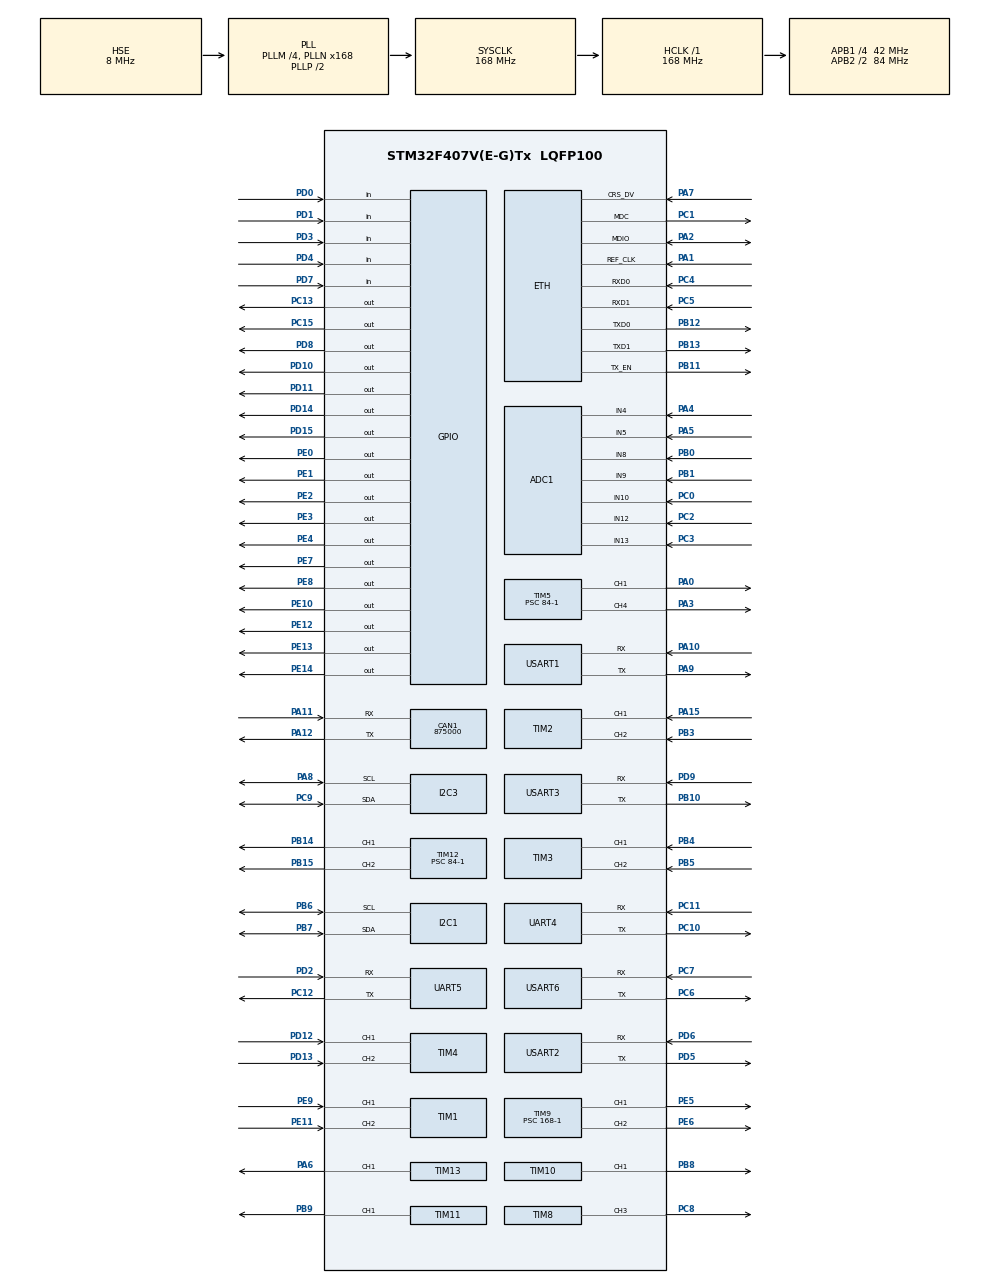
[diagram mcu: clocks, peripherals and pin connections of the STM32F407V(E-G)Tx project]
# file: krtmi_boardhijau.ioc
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ADC1.Channel-0\#ChannelRegularConversion=ADC_CHANNEL_4
ADC1.NbrOfConversionFlag=1
ADC1.Rank-0\#ChannelRegularConversion=1
ADC1.SamplingTime-0\#ChannelRegularConversion=ADC_SAMPLETIME_3CYCLES
ADC1.master=1
CAN1.CalculateBaudRate=875000
CAN1.CalculateTimeBit=1142
CAN1.CalculateTimeQuantum=380.95238095238096
Dma.Request0=UART4_RX
Dma.Request1=UART4_TX
Dma.Request2=UART5_RX
Dma.Request3=UART5_TX
Dma.Request4=USART2_RX
Dma.Request5=USART2_TX
Dma.Request6=USART3_RX
Dma.Request7=USART3_TX
Dma.Request8=USART6_RX
Dma.Request9=USART6_TX
Dma.UART4_RX.0.Direction=DMA_PERIPH_TO_MEMORY
Dma.UART4_RX.0.FIFOMode=DMA_FIFOMODE_DISABLE
Dma.UART4_RX.0.Instance=DMA1_Stream2
Dma.UART4_RX.0.MemDataAlignment=DMA_MDATAALIGN_BYTE
Dma.UART4_RX.0.MemInc=DMA_MINC_ENABLE
Dma.UART4_RX.0.Mode=DMA_NORMAL
Dma.UART4_RX.0.PeriphDataAlignment=DMA_PDATAALIGN_BYTE
Dma.UART4_RX.0.PeriphInc=DMA_PINC_DISABLE
Dma.UART4_RX.0.Priority=DMA_PRIORITY_LOW
Dma.UART4_TX.1.Direction=DMA_MEMORY_TO_PERIPH
Dma.UART4_TX.1.FIFOMode=DMA_FIFOMODE_DISABLE
Dma.UART4_TX.1.Instance=DMA1_Stream4
Dma.UART4_TX.1.MemDataAlignment=DMA_MDATAALIGN_BYTE
Dma.UART4_TX.1.MemInc=DMA_MINC_ENABLE
Dma.UART4_TX.1.Mode=DMA_NORMAL
Dma.UART4_TX.1.PeriphDataAlignment=DMA_PDATAALIGN_BYTE
Dma.UART4_TX.1.PeriphInc=DMA_PINC_DISABLE
Dma.UART4_TX.1.Priority=DMA_PRIORITY_LOW
Dma.UART5_RX.2.Direction=DMA_PERIPH_TO_MEMORY
Dma.UART5_RX.2.FIFOMode=DMA_FIFOMODE_DISABLE
Dma.UART5_RX.2.Instance=DMA1_Stream0
Dma.UART5_RX.2.MemDataAlignment=DMA_MDATAALIGN_BYTE
Dma.UART5_RX.2.MemInc=DMA_MINC_ENABLE
Dma.UART5_RX.2.Mode=DMA_NORMAL
Dma.UART5_RX.2.PeriphDataAlignment=DMA_PDATAALIGN_BYTE
Dma.UART5_RX.2.PeriphInc=DMA_PINC_DISABLE
Dma.UART5_RX.2.Priority=DMA_PRIORITY_HIGH
Dma.UART5_TX.3.Direction=DMA_MEMORY_TO_PERIPH
Dma.UART5_TX.3.FIFOMode=DMA_FIFOMODE_DISABLE
Dma.UART5_TX.3.Instance=DMA1_Stream7
Dma.UART5_TX.3.MemDataAlignment=DMA_MDATAALIGN_BYTE
Dma.UART5_TX.3.MemInc=DMA_MINC_ENABLE
Dma.UART5_TX.3.Mode=DMA_NORMAL
Dma.UART5_TX.3.PeriphDataAlignment=DMA_PDATAALIGN_BYTE
Dma.UART5_TX.3.PeriphInc=DMA_PINC_DISABLE
Dma.UART5_TX.3.Priority=DMA_PRIORITY_HIGH
Dma.USART2_RX.4.Direction=DMA_PERIPH_TO_MEMORY
Dma.USART2_RX.4.FIFOMode=DMA_FIFOMODE_DISABLE
Dma.USART2_RX.4.Instance=DMA1_Stream5
Dma.USART2_RX.4.MemDataAlignment=DMA_MDATAALIGN_BYTE
Dma.USART2_RX.4.MemInc=DMA_MINC_ENABLE
Dma.USART2_RX.4.Mode=DMA_NORMAL
Dma.USART2_RX.4.PeriphDataAlignment=DMA_PDATAALIGN_BYTE
Dma.USART2_RX.4.PeriphInc=DMA_PINC_DISABLE
Dma.USART2_RX.4.Priority=DMA_PRIORITY_LOW
Dma.USART2_TX.5.Direction=DMA_MEMORY_TO_PERIPH
Dma.USART2_TX.5.FIFOMode=DMA_FIFOMODE_DISABLE
Dma.USART2_TX.5.Instance=DMA1_Stream6
Dma.USART2_TX.5.MemDataAlignment=DMA_MDATAALIGN_BYTE
Dma.USART2_TX.5.MemInc=DMA_MINC_ENABLE
Dma.USART2_TX.5.Mode=DMA_NORMAL
Dma.USART2_TX.5.PeriphDataAlignment=DMA_PDATAALIGN_BYTE
Dma.USART2_TX.5.PeriphInc=DMA_PINC_DISABLE
Dma.USART2_TX.5.Priority=DMA_PRIORITY_LOW
Dma.USART3_RX.6.Direction=DMA_PERIPH_TO_MEMORY
Dma.USART3_RX.6.FIFOMode=DMA_FIFOMODE_DISABLE
Dma.USART3_RX.6.Instance=DMA1_Stream1
Dma.USART3_RX.6.MemDataAlignment=DMA_MDATAALIGN_BYTE
Dma.USART3_RX.6.MemInc=DMA_MINC_ENABLE
Dma.USART3_RX.6.Mode=DMA_NORMAL
Dma.USART3_RX.6.PeriphDataAlignment=DMA_PDATAALIGN_BYTE
Dma.USART3_RX.6.PeriphInc=DMA_PINC_DISABLE
Dma.USART3_RX.6.Priority=DMA_PRIORITY_LOW
Dma.USART3_TX.7.Direction=DMA_MEMORY_TO_PERIPH
Dma.USART3_TX.7.FIFOMode=DMA_FIFOMODE_DISABLE
Dma.USART3_TX.7.Instance=DMA1_Stream3
Dma.USART3_TX.7.MemDataAlignment=DMA_MDATAALIGN_BYTE
Dma.USART3_TX.7.MemInc=DMA_MINC_ENABLE
Dma.USART3_TX.7.Mode=DMA_NORMAL
Dma.USART3_TX.7.PeriphDataAlignment=DMA_PDATAALIGN_BYTE
Dma.USART3_TX.7.PeriphInc=DMA_PINC_DISABLE
Dma.USART3_TX.7.Priority=DMA_PRIORITY_LOW
Dma.USART6_RX.8.Direction=DMA_PERIPH_TO_MEMORY
Dma.USART6_RX.8.FIFOMode=DMA_FIFOMODE_DISABLE
Dma.USART6_RX.8.Instance=DMA2_Stream1
Dma.USART6_RX.8.MemDataAlignment=DMA_MDATAALIGN_BYTE
Dma.USART6_RX.8.MemInc=DMA_MINC_ENABLE
Dma.USART6_RX.8.Mode=DMA_NORMAL
Dma.USART6_RX.8.PeriphDataAlignment=DMA_PDATAALIGN_BYTE
Dma.USART6_RX.8.PeriphInc=DMA_PINC_DISABLE
Dma.USART6_RX.8.Priority=DMA_PRIORITY_LOW
Dma.USART6_TX.9.Direction=DMA_MEMORY_TO_PERIPH
Dma.USART6_TX.9.FIFOMode=DMA_FIFOMODE_DISABLE
Dma.USART6_TX.9.Instance=DMA2_Stream6
Dma.USART6_TX.9.MemDataAlignment=DMA_MDATAALIGN_BYTE
Dma.USART6_TX.9.MemInc=DMA_MINC_ENABLE
Dma.USART6_TX.9.Mode=DMA_NORMAL
Dma.USART6_TX.9.PeriphDataAlignment=DMA_PDATAALIGN_BYTE
Dma.USART6_TX.9.PeriphInc=DMA_PINC_DISABLE
Dma.USART6_TX.9.Priority=DMA_PRIORITY_LOW
ETH.MACAddr=12\:34\:56\:12\:34\:56
ETH.MediaInterface=HAL_ETH_RMII_MODE
LWIP.BSP.number=1
LWIP.GATEWAY_ADDRESS=192.168.013.100
LWIP.IP_ADDRESS=192.168.013.111
LWIP.LWIP_DHCP=0
LWIP.MEM_SIZE=10*1024
LWIP.NETMASK_ADDRESS=255.255.255.000
LWIP.Version=v2.1.2_Cube
LWIP0.BSP.STBoard=false
LWIP0.BSP.api=BSP_COMPONENT_DRIVER
LWIP0.BSP.component=LAN8742
LWIP0.BSP.instance=LAN8742
LWIP0.BSP.name=Driver_PHY
LWIP0.BSP.semaphore=S_LAN8742
LWIP0.BSP.solution=LAN8742
Mcu.Family=STM32F4
Mcu.Name=STM32F407V(E-G)Tx
Mcu.Package=LQFP100
NVIC.DMA1_Stream0_IRQn=true\:0\:0\:false\:false\:true\:false\:true\:true
NVIC.DMA1_Stream1_IRQn=true\:0\:0\:false\:false\:true\:false\:true\:true
NVIC.DMA1_Stream2_IRQn=true\:0\:0\:false\:false\:true\:false\:true\:true
NVIC.DMA1_Stream3_IRQn=true\:0\:0\:false\:false\:true\:false\:true\:true
NVIC.DMA1_Stream4_IRQn=true\:0\:0\:false\:false\:true\:false\:true\:true
NVIC.DMA1_Stream5_IRQn=true\:0\:0\:false\:false\:true\:false\:true\:true
NVIC.DMA1_Stream6_IRQn=true\:0\:0\:false\:false\:true\:false\:true\:true
NVIC.DMA1_Stream7_IRQn=true\:0\:0\:false\:false\:true\:false\:true\:true
NVIC.DMA2_Stream1_IRQn=true\:0\:0\:false\:false\:true\:false\:true\:true
NVIC.DMA2_Stream6_IRQn=true\:0\:0\:false\:false\:true\:false\:true\:true
NVIC.PriorityGroup=NVIC_PRIORITYGROUP_4
NVIC.TIM6_DAC_IRQn=true\:0\:0\:false\:false\:true\:true\:true\:true
NVIC.UART4_IRQn=true\:0\:0\:false\:false\:true\:true\:true\:true
NVIC.UART5_IRQn=true\:0\:0\:false\:false\:true\:true\:true\:true
NVIC.USART2_IRQn=true\:0\:0\:false\:false\:true\:true\:true\:true
NVIC.USART3_IRQn=true\:0\:0\:false\:false\:true\:true\:true\:true
PA0-WKUP.Signal=S_TIM5_CH1
PA1.Mode=RMII
PA1.Signal=ETH_REF_CLK
PA10.Mode=Asynchronous
PA10.Signal=USART1_RX
PA11.Mode=CAN_Activate
PA11.Signal=CAN1_RX
PA12.Mode=CAN_Activate
PA12.Signal=CAN1_TX
PA13.Mode=Serial_Wire
PA13.Signal=SYS_JTMS-SWDIO
PA14.Mode=Serial_Wire
PA14.Signal=SYS_JTCK-SWCLK
PA15.Signal=S_TIM2_CH1_ETR
PA2.Mode=RMII
PA2.Signal=ETH_MDIO
PA3.Signal=S_TIM5_CH4
PA4.Signal=ADCx_IN4
PA5.Signal=ADCx_IN5
PA6.Signal=S_TIM13_CH1
PA7.Mode=RMII
PA7.Signal=ETH_CRS_DV
PA8.Mode=I2C
PA8.Signal=I2C3_SCL
PA9.Mode=Asynchronous
PA9.Signal=USART1_TX
PB0.Signal=ADCx_IN8
PB1.Signal=ADCx_IN9
PB10.Mode=Asynchronous
PB10.Signal=USART3_TX
PB11.Mode=RMII
PB11.Signal=ETH_TX_EN
PB12.Mode=RMII
PB12.Signal=ETH_TXD0
PB13.Mode=RMII
PB13.Signal=ETH_TXD1
PB14.Signal=S_TIM12_CH1
PB15.Signal=S_TIM12_CH2
PB3.Signal=S_TIM2_CH2
PB4.Signal=S_TIM3_CH1
PB5.Signal=S_TIM3_CH2
PB6.Mode=I2C
PB6.Signal=I2C1_SCL
PB7.Mode=I2C
PB7.Signal=I2C1_SDA
PB8.Signal=S_TIM10_CH1
PB9.Signal=S_TIM11_CH1
PC0.Signal=ADCx_IN10
PC1.Mode=RMII
PC1.Signal=ETH_MDC
PC10.Mode=Asynchronous
PC10.Signal=UART4_TX
PC11.Mode=Asynchronous
PC11.Signal=UART4_RX
PC12.Mode=Asynchronous
PC12.Signal=UART5_TX
PC13-ANTI_TAMP.Signal=GPIO_Output
PC15-OSC32_OUT.Signal=GPIO_Output
PC2.Signal=ADCx_IN12
PC3.Signal=ADCx_IN13
PC4.Mode=RMII
PC4.Signal=ETH_RXD0
PC5.Mode=RMII
PC5.Signal=ETH_RXD1
PC6.Mode=Asynchronous
PC6.Signal=USART6_TX
PC7.Mode=Asynchronous
PC7.Signal=USART6_RX
PC8.Signal=S_TIM8_CH3
PC9.Mode=I2C
PC9.Signal=I2C3_SDA
PD0.GPIO_PuPd=GPIO_PULLUP
PD0.Signal=GPIO_Input
PD1.GPIO_PuPd=GPIO_PULLUP
PD1.Signal=GPIO_Input
PD10.Signal=GPIO_Output
PD11.Signal=GPIO_Output
PD12.Signal=S_TIM4_CH1
PD13.Signal=S_TIM4_CH2
PD14.Signal=GPIO_Output
PD15.Signal=GPIO_Output
PD2.Mode=Asynchronous
PD2.Signal=UART5_RX
PD3.GPIO_PuPd=GPIO_PULLUP
PD3.Signal=GPIO_Input
PD4.GPIO_PuPd=GPIO_PULLUP
PD4.Signal=GPIO_Input
PD5.Mode=Asynchronous
PD5.Signal=USART2_TX
PD6.Mode=Asynchronous
PD6.Signal=USART2_RX
PD7.GPIO_PuPd=GPIO_PULLUP
PD7.Signal=GPIO_Input
PD8.Signal=GPIO_Output
PD9.Mode=Asynchronous
PD9.Signal=USART3_RX
PE0.Signal=GPIO_Output
PE1.Signal=GPIO_Output
PE10.Signal=GPIO_Output
PE11.Signal=S_TIM1_CH2
PE12.Signal=GPIO_Output
PE13.Signal=GPIO_Output
PE14.Signal=GPIO_Output
PE2.Signal=GPIO_Output
PE3.Signal=GPIO_Output
PE4.Signal=GPIO_Output
PE5.Signal=S_TIM9_CH1
PE6.Signal=S_TIM9_CH2
PE7.Signal=GPIO_Output
PE8.Signal=GPIO_Output
PE9.Signal=S_TIM1_CH1
PH0-OSC_IN.Mode=HSE-External-Oscillator
PH0-OSC_IN.Signal=RCC_OSC_IN
PH1-OSC_OUT.Mode=HSE-External-Oscillator
PH1-OSC_OUT.Signal=RCC_OSC_OUT
ProjectManager.HeapSize=0x200
ProjectManager.StackSize=0x400
ProjectManager.TargetToolchain=STM32CubeIDE
RCC.48MHZClocksFreq_Value=84000000
RCC.AHBFreq_Value=168000000
RCC.APB1CLKDivider=RCC_HCLK_DIV4
RCC.APB1Freq_Value=42000000
RCC.APB1TimFreq_Value=84000000
RCC.APB2CLKDivider=RCC_HCLK_DIV2
RCC.APB2Freq_Value=84000000
RCC.APB2TimFreq_Value=168000000
RCC.CortexFreq_Value=168000000
RCC.HCLKFreq_Value=168000000
RCC.HSE_VALUE=8000000
RCC.HSI_VALUE=16000000
RCC.LSE_VALUE=32768
RCC.PLLM=4
RCC.PLLN=168
RCC.PLLSourceVirtual=RCC_PLLSOURCE_HSE
RCC.SYSCLKFreq_VALUE=168000000
RCC.SYSCLKSource=RCC_SYSCLKSOURCE_PLLCLK
RCC.VCOOutputFreq_Value=336000000
SH.ADCx_IN10.0=ADC1_IN10,IN10
SH.ADCx_IN12.0=ADC1_IN12,IN12
SH.ADCx_IN13.0=ADC1_IN13,IN13
SH.ADCx_IN4.0=ADC1_IN4,IN4
SH.ADCx_IN5.0=ADC1_IN5,IN5
SH.ADCx_IN8.0=ADC1_IN8,IN8
SH.ADCx_IN9.0=ADC1_IN9,IN9
SH.S_TIM10_CH1.0=TIM10_CH1,PWM Generation1 CH1
SH.S_TIM11_CH1.0=TIM11_CH1,PWM Generation1 CH1
SH.S_TIM12_CH1.0=TIM12_CH1,PWM Generation1 CH1
SH.S_TIM12_CH2.0=TIM12_CH2,PWM Generation2 CH2
SH.S_TIM13_CH1.0=TIM13_CH1,PWM Generation1 CH1
SH.S_TIM1_CH1.0=TIM1_CH1,Encoder_Interface
SH.S_TIM1_CH2.0=TIM1_CH2,Encoder_Interface
SH.S_TIM2_CH1_ETR.0=TIM2_CH1,Encoder_Interface
SH.S_TIM2_CH2.0=TIM2_CH2,Encoder_Interface
SH.S_TIM3_CH1.0=TIM3_CH1,Encoder_Interface
SH.S_TIM3_CH2.0=TIM3_CH2,Encoder_Interface
SH.S_TIM4_CH1.0=TIM4_CH1,Encoder_Interface
SH.S_TIM4_CH2.0=TIM4_CH2,Encoder_Interface
SH.S_TIM5_CH1.0=TIM5_CH1,PWM Generation1 CH1
SH.S_TIM5_CH4.0=TIM5_CH4,PWM Generation4 CH4
SH.S_TIM8_CH3.0=TIM8_CH3,PWM Generation3 CH3
SH.S_TIM9_CH1.0=TIM9_CH1,PWM Generation1 CH1
SH.S_TIM9_CH2.0=TIM9_CH2,PWM Generation2 CH2
TIM10.Channel=TIM_CHANNEL_1
TIM10.Period=1000-1
TIM10.Prescaler=168-1
TIM11.Channel=TIM_CHANNEL_1
TIM11.Period=1000-1
TIM11.Prescaler=168-1
TIM12.Channel-PWM\ Generation1\ CH1=TIM_CHANNEL_1
TIM12.Channel-PWM\ Generation2\ CH2=TIM_CHANNEL_2
TIM12.Period=1000-1
TIM12.Prescaler=84-1
TIM13.Channel=TIM_CHANNEL_1
TIM13.Period=1000-1
TIM13.Prescaler=84-1
TIM5.Channel-PWM\ Generation1\ CH1=TIM_CHANNEL_1
TIM5.Channel-PWM\ Generation4\ CH4=TIM_CHANNEL_4
TIM5.Period=1000-1
TIM5.Prescaler=84-1
TIM6.Period=1000 - 1
TIM6.Prescaler=168-1
TIM8.Channel-PWM\ Generation3\ CH3=TIM_CHANNEL_3
TIM8.Period=1000-1
TIM8.Prescaler=168-1
TIM9.Channel-PWM\ Generation1\ CH1=TIM_CHANNEL_1
TIM9.Channel-PWM\ Generation2\ CH2=TIM_CHANNEL_2
TIM9.Period=1000-1
TIM9.Prescaler=168-1
UART4.VirtualMode=Asynchronous
UART5.VirtualMode=Asynchronous
USART1.VirtualMode=VM_ASYNC
USART2.VirtualMode=VM_ASYNC
USART3.VirtualMode=VM_ASYNC
USART6.VirtualMode=VM_ASYNC
VP_LWIP_VS_Enabled.Mode=Enabled
VP_TIM10_VS_ClockSourceINT.Mode=Enable_Timer
VP_TIM11_VS_ClockSourceINT.Mode=Enable_Timer
VP_TIM13_VS_ClockSourceINT.Mode=Enable_Timer
VP_TIM6_VS_ClockSourceINT.Mode=Enable_Timer
board=custom

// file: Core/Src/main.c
/* USER CODE BEGIN Header */
/**
  ******************************************************************************
  * @file           : main.c
  * @brief          : Main program body
  ******************************************************************************
  * @attention
  *
  * Copyright (c) 2024 STMicroelectronics.
  * All rights reserved.
  *
  * This software is licensed under terms that can be found in the LICENSE file
  * in the root directory of this software component.
  * If no LICENSE file comes with this software, it is provided AS-IS.
  *
  ******************************************************************************
  */
/* USER CODE END Header */
#include "main.h"
#include "adc.h"
#include "can.h"
#include "dma.h"
#include "i2c.h"
#include "lwip.h"
#include "tim.h"
#include "usart.h"
#include "gpio.h"

/* USER CODE BEGIN Includes */
#include "udpClientRAW.h"
#include "controller.h"
#include "motor.h"
#include "pid.h"
/* USER CODE END Includes */

void SystemClock_Config(void);

/* USER CODE BEGIN 0 */
uint8_t udp_cnt = 0;
uint8_t rst_state = 0;
int16_t rst_cnt = 0;

Motor_t motorA;
Motor_t motorB;
Motor_t motorC;

Encoder_t encA;
Encoder_t encB;
Encoder_t encC;
Encoder_t encX;
Encoder_t encY;

PID_t PID_A;
PID_t PID_B;
PID_t PID_C;

float kp;
float ki;
float kd;

char UART1_RX_BUFFER[53]; //--- VGT ARM
char UART2_RX_BUFFER[23];
char UART3_RX_BUFFER[43];
char UART4_RX_BUFFER[53];
char UART5_RX_BUFFER[23];
char UART6_RX_BUFFER[7];  //--- NANO YAW

char UART1_TX_BUFFER[53] = "ABC";

//float flip_yaw(float original_yaw)
//{
//    return 360.0f - fmodf(original_yaw, 360.0f);
//}

//void yaw_process()
//{
//	static uint8_t offset_once = 0;
//	yaw_degree = flip_yaw(yaw_degree_raw);
//
//	if(yaw_degree > 180.001)
//	{
//		yaw_degree -= 360.001;
//	}
//	else if(yaw_degree < -180.001)
//	{
//		yaw_degree += 360.001;
//	}
//
//	if(input.crs)
//	{
//		yaw_adjust = yaw_degree;
//		vw_controller = 0;
//	}
//
//	if(!offset_once)
//	{
//		yaw_adjust = yaw_degree;
//		offset_once++;
//	}
//
//	yaw_degree = yaw_degree - yaw_adjust;
//
//	yaw_radian = yaw_degree * M_PI/180.0;
//}

//void controller_process()
//{
//	static float arm_set_0 = 0;
//	static float arm_set_1 = 0;
//
//	if(input.r1 && arm_setpoints[0] >= -920)
//	{
//		arm_set_0 -= 0.5;
//	}
//	else if(input.l1 && arm_setpoints[0] <= 920)
//	{
//		arm_set_0 += 0.5;
//	}
//
//
//	if(input.up && arm_setpoints[1] < 2250)
//	{
//		arm_set_1 += 1;
//
//	}
//	else if(input.down && arm_setpoints[1] >= 0)
//	{
//		arm_set_1 -= 1;
//	}
//
//	if(input.tri)
//	{
//		reset_rotation = 1;
//		arm_set_0 = 0;
//	}
//	else
//	{
//		reset_rotation = 0;
//	}

//	arm_setpoints[0] = (int16_t)arm_set_0;
//	arm_setpoints[1] = (int16_t)arm_set_1;
//	arm_setpoints[2] = map(input.r2, 0, 255, 2592 - 50, 35);

//	input.lX = Controller_Drift(input.lX_raw, 12);
//	input.lY = Controller_Drift(input.lY_raw, 12);
//	input.rX = Controller_Drift(input.rX_raw, 12);
//	input.rY = Controller_Drift(input.rY_raw, 12);
//
//	input.lX = map(input.lX, -128, 127, -30, 30);
//	input.lY = map(input.lY, -128, 127, -30, 30);
//	input.rX = map(input.rX, -128, 127, -3, 3);
//	input.rY = map(input.rY, -128, 127, -30, 30);

	//--- Robot Centric
//		vx_controller = input.lX;
//		vy_controller = input.lY;
//		vw_controller = -(input.rX);

	//--- Field Centric
//	vx_controller = input.lX *  cos(yaw_radian) + input.lY * sin(yaw_radian);
//	vy_controller = input.lX * -sin(yaw_radian) + input.lY * cos(yaw_radian);
//	vw_controller += -(input.rX) / 20.0;
//
//    if (vw_controller > 180.0f)
//    {
//    	vw_controller -= 360.0f;
//    }
//    else if (vw_controller < -180.0f)
//    {
//    	vw_controller += 360.0f;
//    }
//
//	vx = vx_controller;
//	vy = vy_controller;
//	vw = vw_controller;
//}

void Robot_Init()
{
	Motor_Init(	&motorA,
				GPIOC, GPIO_PIN_15,
				GPIOC, GPIO_PIN_13,
				&htim11, TIM_CHANNEL_1, 1);

	Motor_Init(	&motorB,
				GPIOE, GPIO_PIN_3,
				GPIOE, GPIO_PIN_0,
				&htim10, TIM_CHANNEL_1, 0);

	Motor_Init(	&motorC,
				GPIOD, GPIO_PIN_10,
				GPIOD, GPIO_PIN_8,
				&htim12, TIM_CHANNEL_1, 1);

	Encoder_Init(&encA, &htim3, 0);
	Encoder_Init(&encB, &htim4, 1);
	Encoder_Init(&encC, &htim2, 0);

	kp = 45;
	ki = 2.5;
	kd = 0;

    PID_Init(&PID_A, kp, ki, kd);
    PID_Init(&PID_B, kp, ki, kd);
    PID_Init(&PID_C, kp, ki, kd);

    HAL_UART_Receive_DMA(&huart1, (uint8_t*)UART1_RX_BUFFER, sizeof(UART1_RX_BUFFER));
    HAL_UART_Receive_DMA(&huart2, (uint8_t*)UART2_RX_BUFFER, sizeof(UART2_RX_BUFFER));
    HAL_UART_Receive_DMA(&huart3, (uint8_t*)UART3_RX_BUFFER, sizeof(UART3_RX_BUFFER));
    HAL_UART_Receive_DMA(&huart4, (uint8_t*)UART4_RX_BUFFER, sizeof(UART4_RX_BUFFER));
    HAL_UART_Receive_DMA(&huart5, (uint8_t*)UART5_RX_BUFFER, sizeof(UART5_RX_BUFFER));
    HAL_UART_Receive_DMA(&huart6, (uint8_t*)UART6_RX_BUFFER, sizeof(UART6_RX_BUFFER));

	udpClient_connect();

	HAL_TIM_Base_Start_IT(&htim6);
}

void Robot_Motor()
{
	static uint16_t timer = 0;

	if(timer >= 9)
	{
//		float avg_distance = (UltraSonic[0] + UltraSonic[1]) / 2;
//
//		PID_Update(&PID_VY, 20, avg_distance, 5);
//
//		PID_Update(&PID_VW, UltraSonic[0], UltraSonic[1], 5);

//		PID_Update_Rotate(&PID_VW, vw, yaw_degree, 5);
//
//		int16_t va = Kinematics_Triangle(MOTOR_A, vx, vy, (int16_t)PID_VW.output);
//		int16_t vb = Kinematics_Triangle(MOTOR_B, vx, vy, (int16_t)PID_VW.output);
//		int16_t vc = Kinematics_Triangle(MOTOR_C, vx, vy, (int16_t)PID_VW.output);

//		int16_t va = udp_rx.motor_a;
//		int16_t vb = udp_rx.motor_b;
//		int16_t vc = udp_rx.motor_c;

		Encoder_GetCount(&encA);
		Encoder_GetCount(&encB);
		Encoder_GetCount(&encC);

		/* Save UDP */
		udp_tx.enc_a = encA.count;
		udp_tx.enc_b = encB.count;
		udp_tx.enc_c = encC.count;

		Encoder_ResetCount(&encA);
		Encoder_ResetCount(&encB);
		Encoder_ResetCount(&encC);

		PID_Update(&PID_A, udp_rx.motorA_setpoint, (float)encA.count, 999);
		PID_Update(&PID_B, udp_rx.motorB_setpoint, (float)encB.count, 999);
		PID_Update(&PID_C, udp_rx.motorC_setpoint, (float)encC.count, 999);

		Motor_Run(&motorA, (int16_t)PID_A.output);
		Motor_Run(&motorB, (int16_t)PID_B.output);
		Motor_Run(&motorC, (int16_t)PID_C.output);

		timer = 0;
	}

	timer++;
}

void Robot_LED_Blink()
{
	static uint16_t timer = 0;
	static uint8_t state = 0;

	if(timer >= 99)
	{
		state = !(state);
		HAL_GPIO_WritePin(GPIOE, GPIO_PIN_1, state);
		timer = 0;
	}

	timer++;
}

void Robot_Transmit_UART()
{
	//--- VGT ARM
	memcpy(UART1_TX_BUFFER + 3, &udp_rx.robot_start, 1);
	memcpy(UART1_TX_BUFFER + 4, &rst_state, 1);
	memcpy(UART1_TX_BUFFER + 5, &udp_rx.relay_state, 1);
	memcpy(UART1_TX_BUFFER + 6, &udp_rx.rotation_setpoint, 2);
	memcpy(UART1_TX_BUFFER + 8, &udp_rx.horizontal_setpoint, 2);
	memcpy(UART1_TX_BUFFER + 10, &udp_rx.vertical_setpoint, 2);

	HAL_UART_Transmit_DMA(&huart1, (uint8_t*)UART1_TX_BUFFER, sizeof(UART1_TX_BUFFER));
}

void Read_Buttons()
{
	udp_tx.start_button = HAL_GPIO_ReadPin(GPIOD, GPIO_PIN_0);
	udp_tx.reset_button = HAL_GPIO_ReadPin(GPIOD, GPIO_PIN_1);
	udp_tx.buttons[0] = HAL_GPIO_ReadPin(GPIOD, GPIO_PIN_4);
	udp_tx.buttons[1] = HAL_GPIO_ReadPin(GPIOD, GPIO_PIN_7);
	udp_tx.buttons[2] = HAL_GPIO_ReadPin(GPIOD, GPIO_PIN_3);

	if(udp_tx.reset_button == 0)
	{
		rst_state = 1;
	}
}

void Robot_Loop()
{
	if(rst_state)
	{
		if(rst_cnt >= 500)
		{
			NVIC_SystemReset();
		}
		else
		{
			rst_cnt++;
		}
	}

	Read_Buttons();

	Robot_Transmit_UART();

	Robot_Motor();

	Robot_LED_Blink();

	udp_cnt++;
}

void HAL_TIM_PeriodElapsedCallback(TIM_HandleTypeDef *htim)
{

	if(htim == &htim6)
	{
		Robot_Loop();
	}
}

void HAL_UART_RxCpltCallback(UART_HandleTypeDef *huart)
{
	if(huart == &huart1) //--- VGT ARM
	{
		if(UART1_RX_BUFFER[0] == 'A' && UART1_RX_BUFFER[1] == 'B' && UART1_RX_BUFFER[2] == 'C')
		{
			/* Save UDP */
			memcpy(&udp_tx.buttons[3], UART1_RX_BUFFER + 3, 1);
			memcpy(&udp_tx.buttons[4], UART1_RX_BUFFER + 4, 1);
			memcpy(&udp_tx.lim2, UART1_RX_BUFFER + 5, 1);
			memcpy(&udp_tx.lim3, UART1_RX_BUFFER + 6, 1);
			memcpy(&udp_tx.enc_1, UART1_RX_BUFFER + 7, 2);
			memcpy(&udp_tx.enc_2, UART1_RX_BUFFER + 9, 2);
			memcpy(&udp_tx.enc_3, UART1_RX_BUFFER + 11, 2);
		}
		HAL_UART_Receive_DMA(&huart1, (uint8_t*)UART1_RX_BUFFER, sizeof(UART1_RX_BUFFER));
	}

//	if(huart == &huart2)
//	{
//		memcpy(&yaw_degree, UART2_RX_BUFFER + 3, 4);
//
//		yaw_radian = (yaw_degree - yaw_adjust) * M_PI/180.0;
//
//		/* Save UDP */
//		udp_tx.yaw_degree = yaw_degree;
//
//		HAL_UART_Receive_DMA(&huart2, (uint8_t*)UART2_RX_BUFFER, sizeof(UART2_RX_BUFFER));
//	}

	if(huart == &huart3)
	{
		if(UART3_RX_BUFFER[0] == 'A' && UART3_RX_BUFFER[1] == 'B' && UART3_RX_BUFFER[2] == 'C')
		{
			/* Save UDP */
			memcpy(&udp_tx.rX, UART3_RX_BUFFER + 3, 1);
			memcpy(&udp_tx.rY, UART3_RX_BUFFER + 4, 1);
			memcpy(&udp_tx.lX, UART3_RX_BUFFER + 5, 1);
			memcpy(&udp_tx.lY, UART3_RX_BUFFER + 6, 1);

			memcpy(&udp_tx.r2, UART3_RX_BUFFER + 7, 1);
			memcpy(&udp_tx.l2, UART3_RX_BUFFER + 8, 1);
			memcpy(&udp_tx.r1, UART3_RX_BUFFER + 9, 1);
			memcpy(&udp_tx.l1, UART3_RX_BUFFER + 10, 1);
			memcpy(&udp_tx.r3, UART3_RX_BUFFER + 11, 1);
			memcpy(&udp_tx.l3, UART3_RX_BUFFER + 12, 1);

			memcpy(&udp_tx.crs, UART3_RX_BUFFER + 13, 1);
			memcpy(&udp_tx.sqr, UART3_RX_BUFFER + 14, 1);
			memcpy(&udp_tx.tri, UART3_RX_BUFFER + 15, 1);
			memcpy(&udp_tx.cir, UART3_RX_BUFFER + 16, 1);
			memcpy(&udp_tx.up, UART3_RX_BUFFER + 17, 1);
			memcpy(&udp_tx.down, UART3_RX_BUFFER + 18, 1);
			memcpy(&udp_tx.right, UART3_RX_BUFFER + 19, 1);
			memcpy(&udp_tx.left, UART3_RX_BUFFER + 20, 1);
			memcpy(&udp_tx.share, UART3_RX_BUFFER + 21, 1);
			memcpy(&udp_tx.option, UART3_RX_BUFFER + 22, 1);

			memcpy(&udp_tx.ps, UART3_RX_BUFFER + 23, 1);
			memcpy(&udp_tx.touchpad, UART3_RX_BUFFER + 24, 1);
			memcpy(&udp_tx.battery, UART3_RX_BUFFER + 25, 1);

			memcpy(&udp_tx.gX, UART3_RX_BUFFER + 26, 2);
			memcpy(&udp_tx.gY, UART3_RX_BUFFER + 28, 2);
			memcpy(&udp_tx.gZ, UART3_RX_BUFFER + 30, 2);
			memcpy(&udp_tx.aX, UART3_RX_BUFFER + 32, 2);
			memcpy(&udp_tx.aY, UART3_RX_BUFFER + 34, 2);
			memcpy(&udp_tx.aZ, UART3_RX_BUFFER + 36, 2);
		}
		HAL_UART_Receive_DMA(&huart3, (uint8_t*)UART3_RX_BUFFER, sizeof(UART3_RX_BUFFER));
	}

	if(huart == &huart4)
	{
		if(UART4_RX_BUFFER[0] == 'A' && UART4_RX_BUFFER[1] == 'B' && UART4_RX_BUFFER[2] == 'C')
		{
			/* Save UDP */
			memcpy(&udp_tx.ultrasonic[0], UART4_RX_BUFFER + 3, 2);
			memcpy(&udp_tx.ultrasonic[1], UART4_RX_BUFFER + 5, 2);
			memcpy(&udp_tx.ultrasonic[2], UART4_RX_BUFFER + 7, 2);
			memcpy(&udp_tx.ultrasonic[3], UART4_RX_BUFFER + 9, 2);
		}
		HAL_UART_Receive_DMA(&huart4, (uint8_t*)UART4_RX_BUFFER, sizeof(UART4_RX_BUFFER));
	}

	if(huart == &huart5)
	{
		if(UART5_RX_BUFFER[0] == 'A' && UART5_RX_BUFFER[1] == 'B' && UART5_RX_BUFFER[2] == 'C')
		{
			/* Save UDP */
			memcpy(&udp_tx.enc_x, UART5_RX_BUFFER + 3, 2);
			memcpy(&udp_tx.enc_y, UART5_RX_BUFFER + 5, 2);
		}
		HAL_UART_Receive_DMA(&huart5, (uint8_t*)UART5_RX_BUFFER, sizeof(UART5_RX_BUFFER));
	}

	if(huart == &huart6) //--- NANO YAW
	{
		if(UART6_RX_BUFFER[0] == 'A' && UART6_RX_BUFFER[1] == 'B' && UART6_RX_BUFFER[2] == 'C')
		{
			/* Save UDP */
			memcpy(&udp_tx.yaw_degree, UART6_RX_BUFFER + 3, 4);
		}
		HAL_UART_Receive_DMA(&huart6, (uint8_t*)UART6_RX_BUFFER, sizeof(UART6_RX_BUFFER));
	}

}

void HAL_UART_RxHalfCpltCallback(UART_HandleTypeDef *huart)
{
	if(huart == &huart1) //--- VGT ARM
	{
		if(!(UART1_RX_BUFFER[0] == 'A' && UART1_RX_BUFFER[1] == 'B' && UART1_RX_BUFFER[2] == 'C'))
		{
			HAL_UART_AbortReceive(&huart1);
			HAL_UART_Receive_DMA(&huart1, (uint8_t*)UART1_RX_BUFFER, sizeof(UART1_RX_BUFFER));
		}
	}

	if(huart == &huart2)
	{
		if(!(UART2_RX_BUFFER[0] == 'A' && UART2_RX_BUFFER[1] == 'B' && UART2_RX_BUFFER[2] == 'C'))
		{
			HAL_UART_AbortReceive(&huart2);
			HAL_UART_Receive_DMA(&huart2, (uint8_t*)UART2_RX_BUFFER, sizeof(UART2_RX_BUFFER));
		}
	}

	if(huart == &huart3)
	{
		if(!(UART3_RX_BUFFER[0] == 'A' && UART3_RX_BUFFER[1] == 'B' && UART3_RX_BUFFER[2] == 'C'))
		{
			HAL_UART_AbortReceive(&huart3);
			HAL_UART_Receive_DMA(&huart3, (uint8_t*)UART3_RX_BUFFER, sizeof(UART3_RX_BUFFER));
		}
	}

	if(huart == &huart4)
	{
		if(!(UART4_RX_BUFFER[0] == 'A' && UART4_RX_BUFFER[1] == 'B' && UART4_RX_BUFFER[2] == 'C'))
		{
			HAL_UART_AbortReceive(&huart4);
			HAL_UART_Receive_DMA(&huart4, (uint8_t*)UART4_RX_BUFFER, sizeof(UART4_RX_BUFFER));
		}
	}

	if(huart == &huart5)
	{
		if(!(UART5_RX_BUFFER[0] == 'A' && UART5_RX_BUFFER[1] == 'B' && UART5_RX_BUFFER[2] == 'C'))
		{
			HAL_UART_AbortReceive(&huart5);
			HAL_UART_Receive_DMA(&huart5, (uint8_t*)UART5_RX_BUFFER, sizeof(UART5_RX_BUFFER));
		}
	}

	if(huart == &huart6) //--- NANO YAW
	{
		if(!(UART6_RX_BUFFER[0] == 'A' && UART6_RX_BUFFER[1] == 'B' && UART6_RX_BUFFER[2] == 'C'))
		{
			HAL_UART_AbortReceive(&huart6);
			HAL_UART_Receive_DMA(&huart6, (uint8_t*)UART6_RX_BUFFER, sizeof(UART6_RX_BUFFER));
		}
	}

}

void HAL_UART_ErrorCallback(UART_HandleTypeDef *huart)
{
	if(huart == &huart1) //--- VGT ARM
	{
		HAL_UART_AbortReceive(&huart1);
		HAL_UART_Receive_DMA(&huart1, (uint8_t*)UART1_RX_BUFFER, sizeof(UART1_RX_BUFFER));
	}

	if(huart == &huart2)
	{
		HAL_UART_AbortReceive(&huart2);
		HAL_UART_Receive_DMA(&huart2, (uint8_t*)UART2_RX_BUFFER, sizeof(UART2_RX_BUFFER));
	}

	if(huart == &huart3)
	{
		HAL_UART_AbortReceive(&huart3);
		HAL_UART_Receive_DMA(&huart3, (uint8_t*)UART3_RX_BUFFER, sizeof(UART3_RX_BUFFER));
	}

	if(huart == &huart4)
	{
		HAL_UART_AbortReceive(&huart4);
		HAL_UART_Receive_DMA(&huart4, (uint8_t*)UART4_RX_BUFFER, sizeof(UART4_RX_BUFFER));
	}

	if(huart == &huart5)
	{
		HAL_UART_AbortReceive(&huart5);
		HAL_UART_Receive_DMA(&huart5, (uint8_t*)UART5_RX_BUFFER, sizeof(UART5_RX_BUFFER));
	}

	if(huart == &huart6) //--- NANO YAW
	{
		HAL_UART_AbortReceive(&huart6);
		HAL_UART_Receive_DMA(&huart6, (uint8_t*)UART6_RX_BUFFER, sizeof(UART6_RX_BUFFER));

	}

}

/* USER CODE END 0 */

int main(void)
{

  /* MCU Configuration--------------------------------------------------------*/

  /* Reset of all peripherals, Initializes the Flash interface and the Systick. */
  HAL_Init();

  /* Configure the system clock */
  SystemClock_Config();

  /* Initialize all configured peripherals */
  MX_GPIO_Init();
  MX_DMA_Init();
  MX_ADC1_Init();
  MX_CAN1_Init();
  MX_I2C1_Init();
  MX_I2C3_Init();
  MX_TIM1_Init();
  MX_TIM2_Init();
  MX_TIM3_Init();
  MX_TIM4_Init();
  /* Configure the system clock */
  SystemClock_Config();

  /* Initialize all configured peripherals */
  MX_TIM5_Init();
  MX_TIM8_Init();
  MX_TIM9_Init();
  MX_TIM10_Init();
  MX_TIM11_Init();
  MX_TIM12_Init();
  MX_TIM13_Init();
  MX_UART4_Init();
  MX_UART5_Init();
  MX_TIM6_Init();
  MX_USART2_UART_Init();
  MX_USART1_UART_Init();
  MX_USART3_UART_Init();
  MX_USART6_UART_Init();
  MX_LWIP_Init();
  /* USER CODE BEGIN 2 */
  Robot_Init();
  /* USER CODE END 2 */

  /* Infinite loop */
  /* USER CODE BEGIN WHILE */
  while (1)
  {
	  if(udp_cnt >= 1)
	  {
		  MX_LWIP_Process();
		  udpClient_send();
		  udp_cnt = 0;
	  }

    /* USER CODE END WHILE */

  }
}

void SystemClock_Config(void)
{
  RCC_OscInitTypeDef RCC_OscInitStruct = {0};
  RCC_ClkInitTypeDef RCC_ClkInitStruct = {0};

  /** Configure the main internal regulator output voltage
  */
  __HAL_RCC_PWR_CLK_ENABLE();
  __HAL_PWR_VOLTAGESCALING_CONFIG(PWR_REGULATOR_VOLTAGE_SCALE1);

  /** Initializes the RCC Oscillators according to the specified parameters
  * in the RCC_OscInitTypeDef structure.
  */
  RCC_OscInitStruct.OscillatorType = RCC_OSCILLATORTYPE_HSE;
  RCC_OscInitStruct.HSEState = RCC_HSE_ON;
  RCC_OscInitStruct.PLL.PLLState = RCC_PLL_ON;
  RCC_OscInitStruct.PLL.PLLSource = RCC_PLLSOURCE_HSE;
  RCC_OscInitStruct.PLL.PLLM = 4;
  RCC_OscInitStruct.PLL.PLLN = 168;
  RCC_OscInitStruct.PLL.PLLP = RCC_PLLP_DIV2;
  RCC_OscInitStruct.PLL.PLLQ = 4;
  if (HAL_RCC_OscConfig(&RCC_OscInitStruct) != HAL_OK)
  {
    Error_Handler();
  }

  /** Initializes the CPU, AHB and APB buses clocks
  */
  RCC_ClkInitStruct.ClockType = RCC_CLOCKTYPE_HCLK|RCC_CLOCKTYPE_SYSCLK
                              |RCC_CLOCKTYPE_PCLK1|RCC_CLOCKTYPE_PCLK2;
  RCC_ClkInitStruct.SYSCLKSource = RCC_SYSCLKSOURCE_PLLCLK;
  RCC_ClkInitStruct.AHBCLKDivider = RCC_SYSCLK_DIV1;
  RCC_ClkInitStruct.APB1CLKDivider = RCC_HCLK_DIV4;
  RCC_ClkInitStruct.APB2CLKDivider = RCC_HCLK_DIV2;

  if (HAL_RCC_ClockConfig(&RCC_ClkInitStruct, FLASH_LATENCY_5) != HAL_OK)
  {
    Error_Handler();
  }
}

void Error_Handler(void)
{
  __disable_irq();
  while (1)
  {
  }
}
